# tle984x register map
Vendor: Infineon; File version: 1.9.5
CPU: CM0 r2p1, little endian, no MPU, no FPU, 2 interrupt priority bits
Registers are 32-bit, read-write, reset 0x0 unless marked. A register's access mark holds for its fields unless they carry their own. Offsets are from the block's base; [hi:lo] are bit positions; {n}, {i} and the like mark numbered series; 'fields as' and 'values as' point back to an identical list.

## SCU — System Control Unit - Digital Modules (SCU-DM) registers
Base 0x50005000
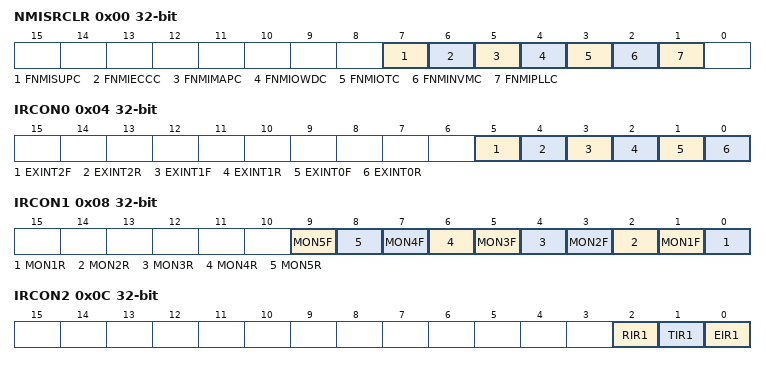
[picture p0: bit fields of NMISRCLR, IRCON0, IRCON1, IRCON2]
0x00 NMISRCLR — NMI status clear register
  [all] fields
    0=NOT_CLEARED (Interrupt event is not cleared); 1=CLEARED (Interrupt event is cleared)
  [7] FNMISUPC wo — Supply prewarning NMI flag
  [6] FNMIECCC wo — ECC error NMI flag
  [5] FNMIMAPC wo — NVM map error NMI flag
  [4] FNMIOWDC wo — Oscillator watchdog NMI flag
  [3] FNMIOTC wo — Overtemperature NMI flag
  [2] FNMINVMC wo — NVM operation complete NMI flag
  [1] FNMIPLLC wo — PLL NMI flag
0x04 IRCON0 ro — Interrupt request 0 register
  [5] EXINT2F — Interrupt flag for external interrupt 2x on falling edge
    0=NOT_OCCURED (Interrupt on falling edge event has not occurred); 1=OCCURED (Interrupt on falling edge event has occurred)
  [4] EXINT2R — Interrupt flag for external interrupt 2x on rising edge
    0=NOT_OCCURED (Interrupt on rising edge event has not occurred); 1=OCCURED (Interrupt on rising edge event has occurred)
  [3] EXINT1F — Interrupt flag for external interrupt 1x on falling edge
    values as EXINT2F
  [2] EXINT1R — Interrupt flag for external interrupt 1x on rising edge
    values as EXINT2R
  [1] EXINT0F — Interrupt flag for external interrupt 0x on falling edge
    values as EXINT2F
  [0] EXINT0R — Interrupt flag for external interrupt 0x on rising edge
    values as EXINT2R
0x08 IRCON1 ro — Interrupt request 1 register
  [2n-1] MON{n}F (n=1..5) — Interrupt flag for MON{n}x on falling edge
    values as IRCON0.EXINT2F
  [2n-2] MON{n}R (n=1..5) — Interrupt flag for MON{n}x on rising edge
    values as IRCON0.EXINT2R
0x0C IRCON2 ro — Interrupt request 2 register
  [all] fields
    0=NOT_OCCURED (Interrupt event has not occurred); 1=OCCURED (Interrupt event has occurred)
  [2] RIR1 — Receive interrupt flag for SSC1
  [1] TIR1 — Transmit interrupt flag for SSC1
  [0] EIR1 — Error interrupt flag for SSC1
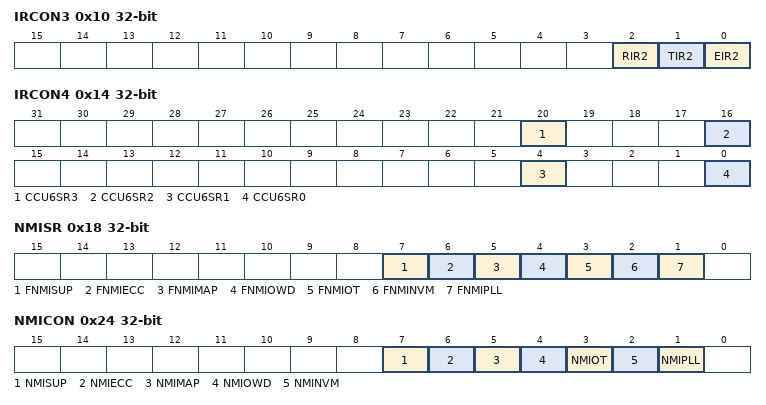
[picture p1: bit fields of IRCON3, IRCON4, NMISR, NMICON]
0x10 IRCON3 ro — Interrupt request 3 register
  [all] fields
    values as the fields of IRCON2
  [2] RIR2 — Receive interrupt flag for SSC2
  [1] TIR2 — Transmit interrupt flag for SSC2
  [0] EIR2 — Error interrupt flag for SSC2
0x14 IRCON4 ro — Interrupt request 4 register
  [all] fields
    values as the fields of IRCON2
  [20] CCU6SR3 — Interrupt flag 3 for CCU6
  [16] CCU6SR2 — Interrupt flag 2 for CCU6
  [4] CCU6SR1 — Interrupt flag 1 for CCU6
  [0] CCU6SR0 — Interrupt flag 0 for CCU6
0x18 NMISR ro — NMI status register
  [7] FNMISUP — Supply prewarning NMI flag
    0=NO_PREWARN (No supply prewarning NMI has occurred); 1=PREWARN (Supply prewarning has occurred)
  [6] FNMIECC — ECC error NMI flag
    0=NO_ECC (No uncorrectable ECC error has occurred on NVM, XRAM); 1=ECC (Uncorrectable ECC error has occurred on NVM, RAM)
  [5] FNMIMAP — NVM map error NMI flag
    0=NO_NVM (No NVM map error NMI has occurred); 1=NVM (NVM map error has occurred)
  [4] FNMIOWD — Oscillator watchdog NMI flag
    0=NO_OSCILLATOR (No oscillator watchdog NMI has occurred); 1=OSCILLATOR (Oscillator watchdog event has occurred)
  [3] FNMIOT — Overtemperature NMI flag
    0=NO_OT (No OT NMI has occurred); 1=OT (OT NMI event has occurred)
  [2] FNMINVM — NVM operation complete NMI flag
    0=NO_NVM (No NVM NMI has occurred); 1=NVM (NVM operation complete event has occurred)
  [1] FNMIPLL — PLL NMI flag
    0=NO_PLL (No PLL NMI has occurred); 1=PLL (PLL loss-of-lock to the external crystal has occurred)
0x1C IEN0 — Interrupt enable 0 register
  [31] EA — Global interrupt mask
    0=BLOCKED (All pending interrupt requests (except NMI) are blocked from the core); 1=NOT_BLOCKED (Pending interrupt requests are not blocked from the core)
0x20 VTOR — Vector table reallocation register
  [1:0] VTOR_BYP — Vector table bypass mode
    0=NOT_REMAPPED (VTOR is not remapped (ROM) (start address: 0x0000000000)); 1=RAM (VTOR is remapped to RAM (start address: 0x1800000000)); 2=BSL (VTOR is remapped to NVM (start address: 0x1100000000, begin of customer BSL region)); 3=NVM (VTOR is remapped to NVM (start address: begin of NVM linear region after customer BSL region))
0x24 NMICON — NMI control register
  [7] NMISUP — Supply prewarning NMI enable
    0=DISABLED (Supply NMI is disabled); 1=ENABLED (Supply NMI is enabled)
  [6] NMIECC — ECC error NMI enable
    0=DISABLED (ECC Error NMI is disabled); 1=ENABLED (ECC Error NMI is enabled)
  [5] NMIMAP — NVM map error NMI enable
    0=DISABLED (NVM map error NMI is disabled); 1=ENABLED (NVM map error NMI is enabled)
  [4] NMIOWD — Oscillator watchdog NMI enable
    0=DISABLED (Oscillator watchdog NMI is disabled); 1=ENABLED (Oscillator watchdog NMI is enabled)
  [3] NMIOT — NMI OT enable
    0=DISABLED (NMI OT is disabled); 1=ENABLED (NMI OT is enabled)
  [2] NMINVM — NVM operation complete NMI enable
    0=DISABLED (NVM operation complete NMI is disabled); 1=ENABLED (NVM operation complete NMI is enabled)
  [1] NMIPLL — PLL loss of lock NMI enable
    0=DISABLED (PLL loss of lock NMI is disabled); 1=ENABLED (PLL loss of lock NMI is enabled)
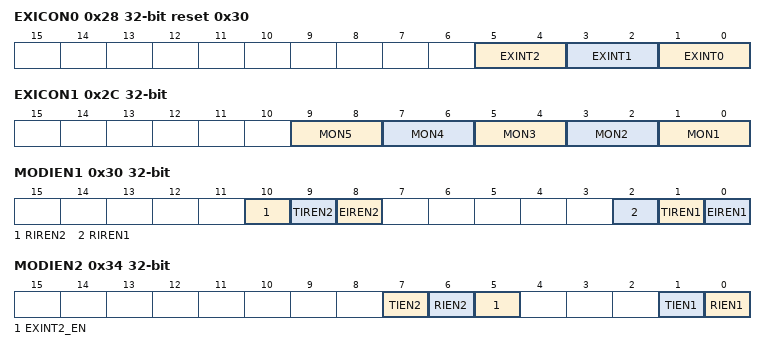
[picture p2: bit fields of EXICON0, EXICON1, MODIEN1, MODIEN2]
0x28 EXICON0 reset 0x30 — External interrupt control 0 register
  [all] fields
    0=DISABLED (Interrupt disabled); 1=RISING (Interrupt on rising edge); 2=FALLING (Interrupt on falling edge); 3=BOTH (Interrupt on both rising and falling edge)
  [5:4] EXINT2 — External interrupt 2 trigger select
  [3:2] EXINT1 — External interrupt 1 trigger select
  [1:0] EXINT0 — External interrupt 0 trigger select
0x2C EXICON1 — External interrupt control 1 register
  [all] fields
    0=DISABLED (External interrupt MON is disabled); 1=RISING (Interrupt on rising edge); 2=FALLING (Interrupt on falling edge); 3=BOTH (Interrupt on both rising and falling edge)
  [2n-1:2n-2] MON{n} (n=1..5) — MON{n} input trigger select
0x30 MODIEN1 — Peripheral interrupt enable 1 register
  [10] RIREN2 — SSC 2 receive interrupt enable
    0=DISABLED (Receive interrupt is disabled); 1=ENABLED (Receive interrupt is enabled)
  [9] TIREN2 — SSC 2 transmit interrupt enable
    0=DISABLED (Transmit interrupt is disabled); 1=ENABLED (Transmit interrupt is enabled)
  [8] EIREN2 — SSC 2 error interrupt enable
    0=DISABLED (Error interrupt is disabled); 1=ENABLED (Error interrupt is enabled)
  [2] RIREN1 — SSC 1 receive interrupt enable
    values as RIREN2
  [1] TIREN1 — SSC 1 transmit interrupt enable
    values as TIREN2
  [0] EIREN1 — SSC 1 error interrupt enable
    values as EIREN2
0x34 MODIEN2 — Peripheral interrupt enable 2 register
  [7] TIEN2 — UART 2 transmit interrupt enable
    values as MODIEN1.TIREN2
  [6] RIEN2 — UART 2 receive interrupt enable
    values as MODIEN1.RIREN2
  [5] EXINT2_EN — External interrupt 2 enable
    0=DISABLED (External interrupt is disabled); 1=ENABLED (External interrupt is enabled)
  [1] TIEN1 — UART 1 transmit interrupt enable
    values as MODIEN1.TIREN2
  [0] RIEN1 — UART 1 receive interrupt enable
    values as MODIEN1.RIREN2
0x38 MODIEN3 — Peripheral interrupt enable 3 register
  [0] IE0 — External interrupt enable
    0=DISABLED; 1=ENABLED
0x3C MODIEN4 — Peripheral interrupt enable 4 register
  [0] IE1 — External interrupt enable
    0=DISABLED; 1=ENABLED
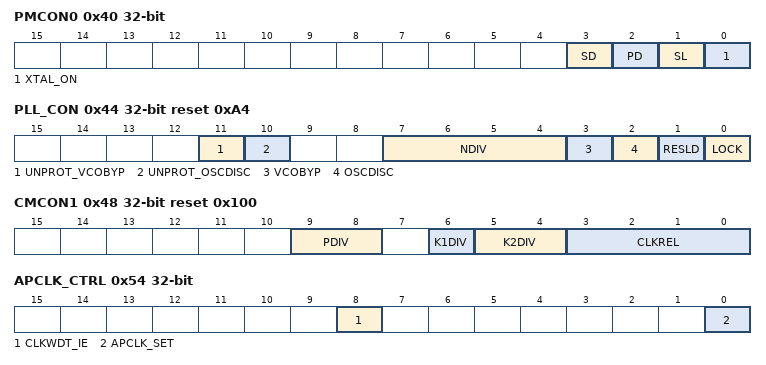
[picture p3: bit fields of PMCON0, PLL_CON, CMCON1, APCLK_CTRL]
0x40 PMCON0 — Power mode control 0 register
  [3] SD — Slow-down mode
    0=INACTIVE (No change); 1=ACTIVE (Device goes into Slow-down mode)
  [2] PD — Power-down mode
    0=INACTIVE (No change); 1=ACTIVE (Device goes into Power-down mode)
  [1] SL — Sleep mode
    0=INACTIVE (No change); 1=ACTIVE (Device goes into Sleep mode)
  [0] XTAL_ON — OSC_HP operation in STOP mode
    0=XTAL_OFF (OSC_HP (XTAL) will be suspended by hardware in STOP mode); 1=XTAL_ON (OSC_HP (XTAL) continues to operate in STOP mode, if enabled by SCU_OSC_CON.XPD)
0x44 PLL_CON reset 0xA4 — PLL control register
  [11] UNPROT_VCOBYP wo — Unprotect write access of VCO_BYP
  [10] UNPROT_OSCDISC wo — Unprotect write access of OSC_DISC
  [7:4] NDIV — PLL N-divider
    0=N = 48; 1=N = 50; 2=N = 51; 3=N = 52; 4=N = 54; 5=N = 60; 6=N = 67; 7=N = 72; 8=N = 75; 9=N = 78; 10=N = 80; 11=N = 88; 12=N = 90; 13=N =94; 14=N = 100; 15=N = 160
  [3] VCOBYP — PLL VCO bypass mode select
    0=NORMAL (Normal (or free running) operation (default)); 1=PRESCALER (Prescaler mode; VCO is bypassed (PLL output clock is derived from input clock divided by K1-divider))
  [2] OSCDISC — Oscillator disconnect
    0=CONNECTED (Oscillator is connected to the PLL); 1=DISCONNECTED (Oscillator is disconnected to the PLL)
  [1] RESLD — Restart lock detection
    0=NO (No effect); 1=RESET (Reset lock flag and restart lock detection)
  [0] LOCK ro — PLL lock status flag
    0=UNLOCKED (The frequency difference of fREF and fDIV is greater than allowed. The VCO part of the PLL can not lock on a target frequency); 1=LOCKED (The frequency difference of fREF and fDIV is small enough to enable a stable VCO operation)
0x48 CMCON1 reset 0x100 — Clock control 1 register
  [9:8] PDIV — PLL PDIV-divider
    0=4; 1=5 (default); 2=6_1; 3=6_2
  [6] K1DIV — PLL K1-divider
    0=K1 = 2; 1=K1 = 1
  [5:4] K2DIV — PLL K2-divider
    {v}=K2 = {v+2} (v=0..3)
  [3:0] CLKREL — Slow down clock divider for fCCLK generation
    0=fSYS; 1=fSYS/2; 2=fSYS/3; 3=fSYS/4; 4=fSYS/8; 5=fSYS/16; 6=fSYS/24; 7=fSYS/32; 8=fSYS/48; 9=fSYS/64; 10=fSYS/96; 11=fSYS/128; 12=fSYS/192; 13=fSYS/256; 14=fSYS/384; 15=fSYS/512
0x4C CMCON2 — Clock control 2 register
  [0] PBA0CLKREL — PBA0 clock divider
    0=Divide by 1; 1=Divide by 2
0x54 APCLK_CTRL — Analog peripheral clock control register
  [8] CLKWDT_IE — Clock watchdog interrupt enable
    0=DISABLED (Interrupt disabled); 1=ENABLED (Interrupt enabled)
  [0] APCLK_SET — Set and overtake flag for clock settings
    0=IGNORED (Clock settings are ignored (previous values are held)); 1=OVERTAKEN (Clock settings are overtaken)
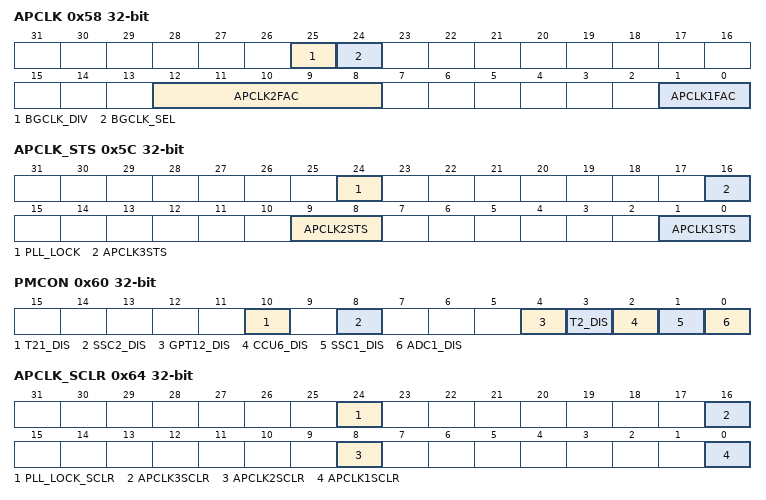
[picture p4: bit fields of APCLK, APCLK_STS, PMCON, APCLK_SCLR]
0x58 APCLK — Analog peripheral clock register
  [25] BGCLK_DIV — Bandgap clock divider
    0=Divide by 2; 1=Divide by 1
  [24] BGCLK_SEL — Bandgap clock selection
    0=LP_CLK (LP_CLK is selected); 1=fSYS is selected
  [12:8] APCLK2FAC — Slow down clock divider for TFILT_CLK generation
    0=fSYS; {v}=fSYS/{v+1} (v=1..11); 30=fSYS/24; 31=fSYS/32
  [1:0] APCLK1FAC — Analog module clock factor
    {v}=Divide by {v+1} (v=0..3)
0x5C APCLK_STS ro — Analog peripheral clock status register
  [24] PLL_LOCK — PLL LOCK status
    0=NOT_LOCKED (PLL has not locked); 1=LOCKED (PLL has locked)
  [16] APCLK3STS — Loss of clock status
    0=NO_LOSS (No loss of clock); 1=LOSS (Loss of lock occurred)
  [9:8] APCLK2STS — Analog peripherals clock status
    0=RANGE (The TFILT_CLK clock is in the required range); 1=HIGHER (The TFILT_CLK clock exceeds the higher limit); 2=LOWER (The TFILT_CLK clock exceeds the lower limit); 3=OUTSIDE (The TFILT_CLK clock is not inside the specified limit)
  [1:0] APCLK1STS — Analog peripherals clock status
    0=RANGE (The MI_CLK clock is in the required range); 1=HIGHER (The MI_CLK clock exceeds the higher limit); 2=LOWER (The MI_CLK clock exceeds the lower limit); 3=OUTSIDE (The MI_CLK clock is not inside the specified limit)
0x60 PMCON — Peripheral management control register
  [10] T21_DIS — T21 disable request, active high
    0=NORMAL (T21 is in normal operation (default)); 1=DISABLE (Request to disable the T21)
  [8] SSC2_DIS — SSC2 disable request, active high
    0=NORMAL (SSC is in normal operation (default)); 1=DISABLE (Request to disable the SSC)
  [4] GPT12_DIS — General purpose timer 12 disable request, active high
    0=NORMAL (GPT12 is in normal operation (default)); 1=DISABLE (Request to disable the GPT12)
  [3] T2_DIS — T2 disable request, active high
    0=NORMAL (T2 is in normal operation (default)); 1=DISABLE (Request to disable the T2)
  [2] CCU6_DIS — CCU6 disable request, active high
    0=NORMAL (CCU6 is in normal operation (default)); 1=DISABLE (Request to disable the CCU6)
  [1] SSC1_DIS — SSC1 disable request, active high
    values as SSC2_DIS
  [0] ADC1_DIS — ADC1 disable request, active high
    0=NORMAL (ADC1 is in normal operation (default)); 1=DISABLE (Request to disable the ADC)
0x64 APCLK_SCLR — Analog peripheral clock status clear register
  [24] PLL_LOCK_SCLR wo — PLL lock status clear
  [16] APCLK3SCLR wo — Analog peripherals clock 3 status clear
  [8] APCLK2SCLR wo — Analog peripherals clock status clear
  [0] APCLK1SCLR wo — Analog peripherals clock status clear
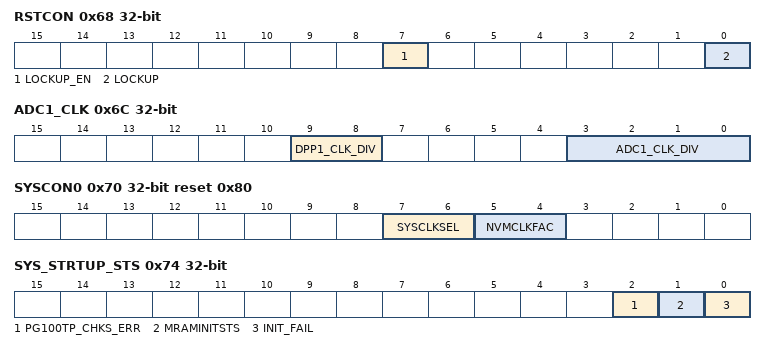
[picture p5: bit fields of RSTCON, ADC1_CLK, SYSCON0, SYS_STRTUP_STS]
0x68 RSTCON — Reset control register
  [7] LOCKUP_EN — Lockup reset enable flag
    0=DISABLED (Lockup is disabled); 1=ENABLED (Lockup is enabled)
  [0] LOCKUP — Lockup flag
    0=NOT_ACTIVE (Lockup status not active); 1=ACTIVE (Lockup status active)
0x6C ADC1_CLK — ADC1 peripheral clock register
  [9:8] DPP1_CLK_DIV — ADC1 post processing clock divider
    {v}=Divide by {v+1} (v=0..3)
  [3:0] ADC1_CLK_DIV — ADC1 clock divider
    0=Divide by {$n+1}; 1=Divide by {$n+1}; 2=Divide by {$n+1}; 3=Divide by {$n+1}; 4=Divide by {$n+1}; 6=Divide by 16
0x70 SYSCON0 reset 0x80 — System control 0 register
  [7:6] SYSCLKSEL — System clock select
    0=PLL (The PLL clock output signal fPLL is used); 1=OSC (The direct clock input from fOSC is used); 2=LP_CLK (The direct low-precision clock input from fLP_CLK is used); 3=INTOSC (The direct input from internal oscillator fINTOSC is used)
  [5:4] NVMCLKFAC — NVM access clock factor
    {v}=Divide by {v+1} (v=0..3)
0x74 SYS_STRTUP_STS — System startup status register
  [2] PG100TP_CHKS_ERR — 100 TP Page checksum error
    0=OK (Initialization of trimming parameters from NMV was successful (checksum was correct)); 1=NOK (Initialization of trimming parameter from NMV was not successful (checksum was notcorrect). As a backup default values form Boot-ROM are used)
  [1] MRAMINITSTS — Map RAM initialization status
    0=NO_FAIL (Map RAM initialization was successful); 1=FAIL (Map RAM initialization was not successful)
  [0] INIT_FAIL — Initialization at startup failed
    0=NO_ERROR (No initialization error at startup); 1=ERROR (Initialization error at startup)
0x78 WAKECON — Wake-up interrupt control register
  [0] WAKEUPEN — Wake-up interrupt enable
    0=DISABLED (Wake-up interrupt is disabled); 1=ENABLED (Wake-up interrupt is enabled)
0x7C IRCON5 ro — Interrupt request 5 register
  [0] WAKEUP — Interrupt flag for wake-up
    values as the fields of IRCON2
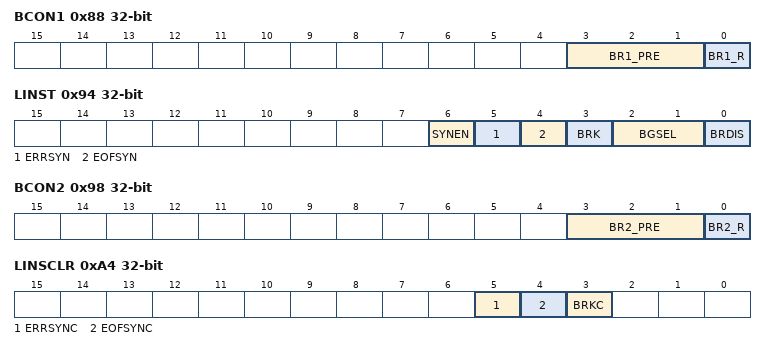
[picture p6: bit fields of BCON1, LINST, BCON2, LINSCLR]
0x88 BCON1 — Baud-rate control 1 register
  [3:1] BR1_PRE — Prescaler bit
    0=fDIV = fPCLK; 1=fDIV = fPCLK/2; 2=fDIV = fPCLK/4; 3=fDIV = fPCLK/8; 4=fDIV = fPCLK/16; 5=fDIV = fPCLK/32
  [0] BR1_R — Baud-rate generator run control bit
    0=DISABLED (Baud-rate generator disabled); 1=ENABLED (Baud-rate generator enabled)
0x8C BGL1 — Baud-rate timer/reload, low byte 1 register
  [4:0] BG1_FD_SEL — Fractional divider selection
0x90 BG1 — Baud-rate timer/reload 1 register
  [10:0] BG1_BR_VALUE — Baud-rate timer/reload value UART1
    0=BYPASSED (Baud-rate timer is bypassed); 1=1; 2=2; 0x7FE=2046; 0x7FF=2047
0x94 LINST — LIN status register
  [6] SYNEN — End of SYN byte and SYN byte error interrupts enable
    0=DISABLED (End of SYN byte and SYN byte error interrupts are not enabled); 1=ENABLED (End of SYN byte and SYN byte error interrupts are enabled)
  [5] ERRSYN ro — SYN byte error interrupt flag
    0=NOT_DETECTED (Error is not detected in SYN byte); 1=DETECTED (Error is detected in SYN byte)
  [4] EOFSYN ro — End of SYN byte interrupt flag
    0=NOT_DETECTED (End of SYN byte is not detected); 1=DETECTED (End of SYN byte is detected)
  [3] BRK ro — Break field flag
    0=NOT_DETECTED (Break field is not detected); 1=DETECTED (Break field is detected)
  [2:1] BGSEL — Baud-rate select for detection
  [0] BRDIS — Baud-rate detection disable
    0=ENABLED (Break/sync detection is enabled); 1=DISABLED (Break/sync detection is disabled)
0x98 BCON2 — Baud-rate control 2 register
  [3:1] BR2_PRE — Prescaler bit
    values as BCON1.BR1_PRE
  [0] BR2_R — Baud-rate generator run control bit
    values as BCON1.BR1_R
0x9C BGL2 — Baud-rate timer/reload, low byte 2 register
  [4:0] BG2_FD_SEL — Fractional divider selection
0xA0 BG2 — Baud-rate timer/reload 2 register
  [10:0] BG2_BR_VALUE — Baud-rate timer/reload value UART2
    values as BG1.BG1_BR_VALUE
0xA4 LINSCLR — LIN status clear register
  [5] ERRSYNC wo — SYN byte error interrupt flag
    0=NOT_CLEARED (Error in SYN byte not cleared); 1=CLEARED (Error in SYN byte cleared)
  [4] EOFSYNC wo — End of SYN byte interrupt flag clear
    0=NOT_CLEARED (End of SYN byte is not cleared); 1=CLEARED (End of SYN byte is cleared)
  [3] BRKC wo — Break field flag clear
    0=NOT_CLEARED (Break field is not cleared); 1=CLEARED (Break field is cleared)
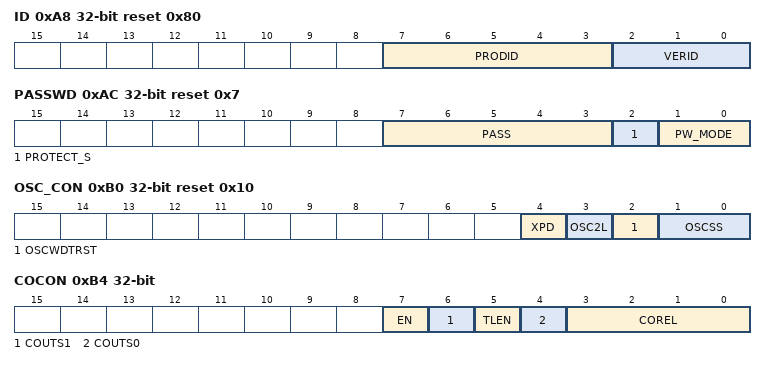
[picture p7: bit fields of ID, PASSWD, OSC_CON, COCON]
0xA8 ID reset 0x80 — Identity register
  [7:3] PRODID ro — Product ID
  [2:0] VERID — Version ID
0xAC PASSWD reset 0x7 — Password register
  [7:3] PASS — Password bits
    19=OPENED (Opens access to writing of all protected bits); 21=CLOSED (Closes access to writing of all protected bits); 24=ENABLED (Enables writing of the bit field MODE)
  [2] PROTECT_S ro — Bit protection signal status bit
    0=NOT_PROTECTED (Software is able to write to all protected bits); 1=PROTECTED (Software is unable to write to any protected bits)
  [1:0] PW_MODE — Bit protection scheme control bit
    0=DISABLED (Scheme disabled); 3=ENABLED (Scheme enabled (default))
0xB0 OSC_CON reset 0x10 — OSC control register
  [4] XPD — XTAL (OSC_HP) power down control
    0=NOT_POWERED (XTAL (OSC_HP) is not powered down); 1=POWERED (XTAL (OSC_HP) is powered down)
  [3] OSC2L ro — OSC-too-low condition flag
    0=ABOVE (fOSC is above threshold); 1=BELOW (fOSC is below threshold)
  [2] OSCWDTRST — Oscillator watchdog reset
    0=NO_EFFECT; 1=RESET (Reset OSC2L flag and restart the oscillator watchdog of the PLL)
  [1:0] OSCSS — Oscillator source select
    0=PLL_SYNC (PLL internal oscillator OSC_PLL (fINT) is selected synchronously as fR); 1=XTAL (XTAL (fOSC from OSC_HP) is selected synchronously as fR); 2=PLL_ASYNC (PLL internal oscillator OSC_PLL (fINT) is selected asynchronously as fR); 3=PLL_ASYNC (PLL internal oscillator OSC_PLL (fINT) is selected asynchronously as fR)
0xB4 COCON — Clock output control register
  [7] EN — CLKOUT enable
    0=NO_EXTERNAL (No external clock signal is provided); 1=EXTERNAL (The configured external clock signal is provided)
  [6] COUTS1 — Clock out source select bit 1
    0=fCCLK is selected; 1=COUTS0 (Based on setting of COUTS0)
  [5] TLEN — Toggle latch enable
    0=DISABLED (Toggle latch is disabled. Clock output frequency is chosen by the bit field COREL); 1=ENABLED (Toggle latch is enabled. Clock output frequency is half of the frequency that is chosen by the bit field COREL. The resulting output frequency has 50% duty cycle)
  [4] COUTS0 — Clock out source select bit 0
    0=OSCILLATOR (Oscillator output frequency is selected); 1=COREL (Clock output frequency is chosen by the bit field COREL)
  [3:0] COREL — Clock output divider
    0=fSYS; 1=fSYS/2; 2=fSYS/3; 3=fSYS/4; 4=fSYS/6; 5=fSYS/8; 6=fSYS/10; 7=fSYS/12; 8=fSYS/14; 9=fSYS/16; 10=fSYS/18; 11=fSYS/20; 12=fSYS/24; 13=fSYS/32; 14=fSYS/36; 15=fSYS/40
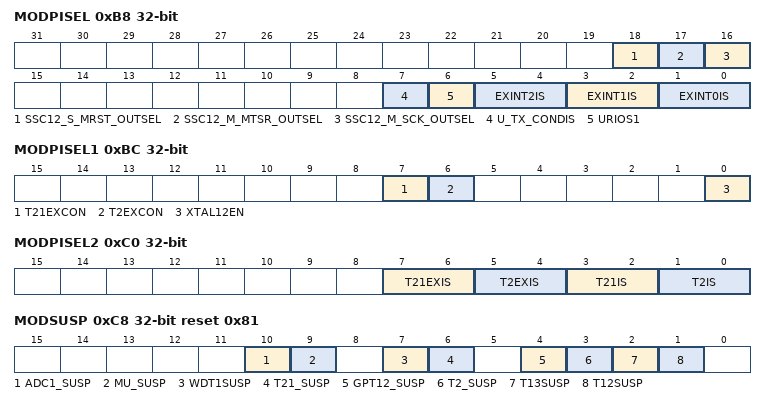
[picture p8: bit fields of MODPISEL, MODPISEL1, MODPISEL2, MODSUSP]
0xB8 MODPISEL — Peripheral input select register
  [18] SSC12_S_MRST_OUTSEL — Output selection for SSC12_S_MRST
    0=SSC1 (SSC1_S_MRST); 1=SSC2 (SSC2_S_MRST)
  [17] SSC12_M_MTSR_OUTSEL — Output selection for SSC12_M_MTSR
    0=SSC1 (SSC1_M_MTSR); 1=SSC2 (SSC2_M_MTSR)
  [16] SSC12_M_SCK_OUTSEL — Output selection for SSC12_M_SCK
    0=SSC1 (SSC1_M_SCK); 1=SSC2 (SSC2_M_SCK)
  [7] U_TX_CONDIS — TRX input select
    0=UART (Transceiver TXD input connected to UART1_TXD output); 1=GPIO (Transceiver TXD input connected to GPIO)
  [6] URIOS1 — UART1 input select
    0=TRX (UART1 receiver input UART1_RXD (connected to transceiver)); 1=GPIO (UART1 receiver input UART1_RXD (connected to GPIO))
  [5:4] EXINT2IS — External interrupt 2 input select
    {v}=EXINT2_{v} (External interrupt input EXINT2_{v} is selected) (v=0..3)
  [3:2] EXINT1IS — External interrupt 1 input select
    {v}=EXINT1_{v} (External interrupt input EXINT1_{v} is selected) (v=0..3)
  [1:0] EXINT0IS — External interrupt 0 input select
    {v}=EXINT0_{v} (External interrupt input EXINT0_{v} is selected) (v=0..3)
0xBC MODPISEL1 — Peripheral input select 1 register
  [7] T21EXCON — Timer 21 external input control
    0=SELECT (Timer21 input T21EX is selected by bit field SCU_MODPISEL2.T21EXIS); 1=CONNECT (Timer21 input T21EX is connected to signal from CCU6 (Output >cc6_ch0))
  [6] T2EXCON — Timer 2 external input control
    0=SELECT (Timer2 input T2EX is selected by bit field SCU_MODPISEL2.T2EXIS); 1=CONNECT (Timer2 input T2EX is connected to signal from CCU6 (Output>cc6_cout60))
  [0] XTAL12EN — Pins XTAL1/2 enable bit
    0=NOT_AVAILABLE (Pins XTAL1/2 is not available. This setting overrides the OSC_CON.XPD setting); 1=AVAILABLE (Pins XTAL1/2 is available)
0xC0 MODPISEL2 — Peripheral input select 2 register
  [7:6] T21EXIS — Timer 21 external input select
    {v}=T21EX_{v} (Timer21 input T21EX_{v} is selected) (v=0..3)
  [5:4] T2EXIS — Timer 2 external input select
    0=T2EX_0 (Timer2 input T2EX_0 is selected); 1=T2EX_1 (Timer2 input T2EX_1 is selected); 2=T2EX_2 (Timer2 input T2EX_2 i selected); 3=T2EX_3 (Timer2 input T2EX_3 is selected)
  [3:2] T21IS — Timer 21 input select
    0=T21_0 (Timer21 input T21_0 is selected); 1=T21_1 (Timer21 input T21_1 is selected); 2=T21_2 (Timer21 input T21_2 is selected)
  [1:0] T2IS — Timer 2 input select
    0=T2_0 (Timer2 input T2_0 is selected); 1=T2_1 (Timer2 input T2_1 is selected); 2=T2_2 (Timer2 input T2_2 is selected)
0xC4 MODPISEL3 — Peripheral input select 3 register
  [6] URIOS2 — UART2 input select
    0=GPIO (UART2 receiver input UART2_RXD (connected to GPIO)); 1=GPIO (UART2 receiver input UART2_RXD (connected to GPIO))
0xC8 MODSUSP reset 0x81 — Module suspend control register
  [10] ADC1_SUSP — ADC1 unit debug suspend bit
    0=NOT_SUSPENDED (ADC1 will not be suspended); 1=SUSPENDED (ADC1 will be suspended)
  [9] MU_SUSP — Measurement unit debug suspend bit
    0=NOT_SUSPENDED (MU will not be suspended); 1=SUSPENDED (MU will be suspended)
  [7] WDT1SUSP — Watchdog timer 1 debug suspend bit
    0=NOT_SUSPENDED (WDT1 will not be suspended); 1=SUSPENDED (WDT1 will be suspended)
  [6] T21_SUSP — Timer 21 debug suspend bit
    0=NOT_SUSPENDED (Timer21 will not be suspended); 1=SUSPENDED (Timer21 will be suspended)
  [4] GPT12_SUSP — GPT12 debug suspend bit
    0=NOT_SUSPENDED (GPT12 will not be suspended); 1=SUSPENDED (GPT12 will be suspended)
  [3] T2_SUSP — Timer 2 debug suspend bit
    0=NOT_SUSPENDED (Timer2 will not be suspended); 1=SUSPENDED (Timer2 will be suspended)
  [2] T13SUSP — Timer 13 debug suspend bit
    0=NOT_SUSPENDED (Timer13 in capture/compare unit will not be suspended); 1=SUSPENDED (Timer13 in capture/compare unit will be suspended)
  [1] T12SUSP — Timer 12 debug suspend bit
    0=NOT_SUSPENDED (Timer12 in capture/compare unit will not be suspended); 1=SUSPENDED (Timer12 in capture/compare unit will be suspended)
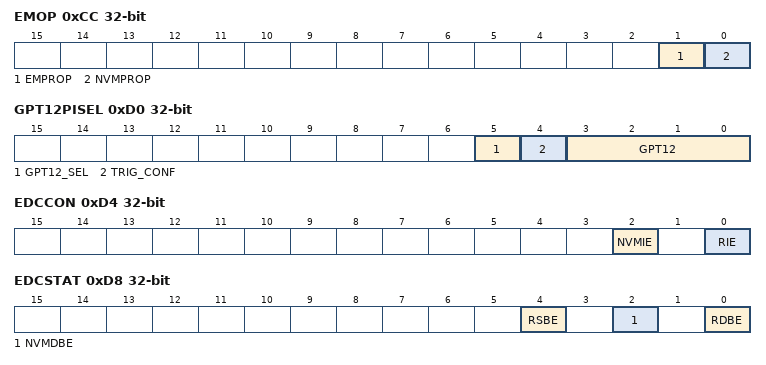
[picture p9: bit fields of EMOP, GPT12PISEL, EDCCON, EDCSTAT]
0xCC EMOP — Emergency and program operation status register
  [1] EMPROP — Emergency program operation status bit
    0=NOT_STARTED (No emergency program operation is started); 1=STARTED (Emergency program operation is started)
  [0] NVMPROP — NVM program operation status bit
    0=NOT_STARTED (No NVM program operation is started); 1=STARTED (NVM program operation is started)
0xD0 GPT12PISEL — GPT12 peripheral input select register
  [5] GPT12_SEL — CCU6 trigger configuration
    0=T21 (CCU6_INT is triggered by Timer21); 1=GPT12 (CCU6_INT is triggered by GPT12PISEL.GPT12)
  [4] TRIG_CONF — CCU6 trigger Configuration
    0=ONE (Trigger is just for one measurement (default)); 1=NEXT (Trigger is present until next input edge (selected by GPT12) \u2013 continuous measurement)
  [3:0] GPT12 — GPT12 T3INB/T4IND input select
    0=CC60; 1=CC61; 2=CC62; 3=T12_ZM; 4=T12_PM; 5=T12_CM0; 6=T12_CM1; 7=T12_CM2; 8=T13_PM; 9=T13_ZM; 10=T13_CM; 11=ANY (Any pos or neg edge on CC60/61/62)
0xD4 EDCCON — Error detection and correction control register
  [2] NVMIE — NVM double bit ECC error interrupt enable
    0=false (No NMI is generated when a double bit ECC error occurs reading NVM); 1=true (An NMI is generated when a double bit ECC error occurs reading NVM)
  [0] RIE — RAM double bit ECC error interrupt enable
    0=false (No NMI is generated when a double bit ECC error occurs reading RAM); 1=true (An NMI is generated when a double bit ECC error occurs reading RAM)
0xD8 EDCSTAT ro — Error detection and correction status register
  [4] RSBE — RAM single bit error
    0=false (No single bit error on RAM has occurred); 1=true (A single bit error on RAM has occurred)
  [2] NVMDBE — NVM double bit error
    0=false (No double bit error on NVM has occurred); 1=true (A double bit error on NVM has occurred)
  [0] RDBE — RAM double bit error
    0=false (No double bit error on RAM has occurred); 1=true (A double bit error on RAM has occurred)
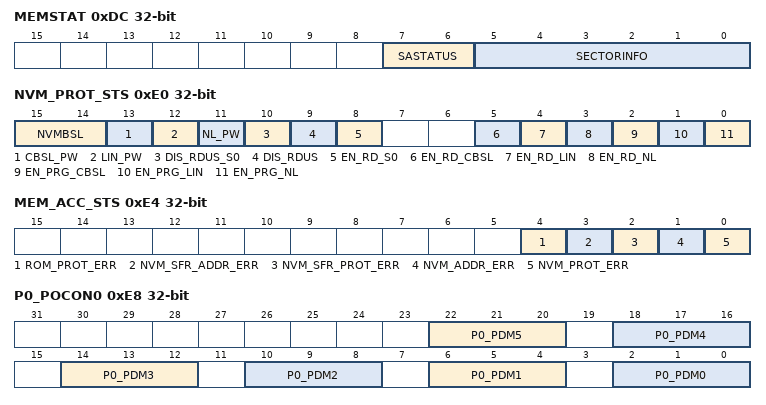
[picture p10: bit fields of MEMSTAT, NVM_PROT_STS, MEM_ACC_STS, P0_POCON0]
0xDC MEMSTAT — Memory status register
  [7:6] SASTATUS — Service algorithm status
    0=SECTORINFO (Depending on SECTORINFO); 1=SUCCESS (SA execution is successful); 2=NO_SUCCESS (SA execution is not successful. Map error exists in the mapped sector); 3=NO_SUCCESS (SA execution is not successful. Map error exists in the mapped sector)
  [5:0] SECTORINFO — Sector information
0xE0 NVM_PROT_STS — NVM protection status register
  [15:14] NVMBSL — CBSL region size definition
    0=CBSL size is 4 K; 1=CBSL size is 8 K; 2=CBSL size is 12 K; 3=CBSL size is 16 K
  [13] CBSL_PW — Status of CBSL region password/protection
    0=NOT_PROTECTED (CBSL region password is not installed; CBSL region is not protected); 1=PROTECTED (CBSL region password is installed; CBSL region is protected)
  [12] LIN_PW — Status of linear region password/protection
    0=NOT_PROTECTED (Linear region password is not installed; linear region is not protected); 1=PROTECTED (Linear region password is installed; linear region is protected)
  [11] NL_PW — Status of non-linear region password/protection
    0=NOT_PROTECTED (Non-linear region password is not installed; linear region is not protected); 1=PROTECTED (Non-linear region password is installed; linear region is protected)
  [10] DIS_RDUS_S0 — Configuration of NVM read protection for sector 0 with EN_RD_S0 = 0
    0=NVM_READ_S0_UNSAVE (Only active when nvm_read_S0_unsafe_i = 1 and not for nvm_read_S0_unsafe_i = 0); 1=INDEPENDENT (Independent from nvm_read_S0_unsafe_i; also write accesses to sector 0 are prevented)
  [9] DIS_RDUS — Configuration of NVM read protection for sector 1...n with EN_RD_* = 0
    0=NVM_READ_UNSAVE (Only active when nvm_read_unsafe_i = 1 and not for nvm_read_unsafe_i = 0); 1=INDEPENTENT (Independent from nvm_read_unsafe_i; also write accesses to sector 1...n are prevented)
  [8] EN_RD_S0 — NVM read protection for sector 0
    0=NO_READ (The data in sector 0 can not be read over AHB-Lite interface); 1=READ (The data in sector 0 can be read over AHB-Lite interface)
  [5] EN_RD_CBSL — NVM read protection of data in CBSL region
    0=NO_READ (The data in region defined by NVMBSL can not be read); 1=READ (The data in region defined by NVMBSL sectors of can be read)
  [4] EN_RD_LIN — NVM read protection of data in linear sectors
    0=NO_READ (The data in sectors of the linearly mapped area can not be read); 1=READ (The data in sectors of the linearly mapped area can be read)
  [3] EN_RD_NL — NVM read protection of data in non-linear sectors
    0=NO_READ (The data in sectors of the non-linearly mapped area can not be read); 1=READ (The data in sectors of the non-linearly mapped area can be read)
  [2] EN_PRG_CBSL — NVM protection of data in CBSL region
    0=NO_CHANGE (The data in region defined by NVMBSL can not be changed); 1=CHANGE (The data in region defined by NVMBSL can be changed (erased or written))
  [1] EN_PRG_LIN — NVM protection of data in linear sectors
    0=NO_CHANGE (The data in sectors of the linearly mapped area can not be changed); 1=CHANGE (The data in sectors of the linearly mapped area can be changed (erased or written))
  [0] EN_PRG_NL — NVM protection of data in non-linear sectors
    0=NO_CHANGE (The data in sectors of the non-linearly mapped area can not be changed); 1=CHANGE (The data in sectors of the non-linearly mapped area can be changed (erased or written))
0xE4 MEM_ACC_STS ro — Memory access status register
  [all] fields
    0=NO_ERROR (No Protection error); 1=ERROR (Protection error)
  [4] ROM_PROT_ERR — ROM access protection
  [3] NVM_SFR_ADDR_ERR — NVM SFR address protection
  [2] NVM_SFR_PROT_ERR — NVM SFR access protection
  [1] NVM_ADDR_ERR — NVM address protection
  [0] NVM_PROT_ERR — NVM access protection
0xE8 P0_POCON0 — Port output control register
  [22:20] P0_PDM5 — P0.5 port driver mode
    0=STRONG_SHARP (Strong driver and sharp edge mode); 1=STRONG_MEDIUM (Strong driver and medium edge mode); 2=STRONG_SOFT (Strong driver and soft edge mode); 3=WEAK_1 (Weak driver 1); 4=MEDIUM_1 (Medium driver 1); 5=MEDIUM_2 (Medium driver 2); 6=MEDIUM_3 (Medium driver 3); 7=WEAK_2 (Weak driver 2)
  [18:16] P0_PDM4 — P0.4 port driver mode
    values as P0_PDM5
  [14:12] P0_PDM3 — P0.3 port driver mode
    values as P0_PDM5
  [10:8] P0_PDM2 — P0.2 port driver mode
    values as P0_PDM5
  [6:4] P0_PDM1 — P0.1 port driver mode
    0=MEDIUM_1 (Medium driver 1); 3=WEAK_1 (Weak driver 1); 4=MEDIUM_2 (Medium driver 2); 5=MEDIUM_3 (Medium driver 3); 6=MEDIUM_4 (Medium driver 4); 7=WEAK_2 (Weak driver 2)
  [2:0] P0_PDM0 — P0.0 port driver mode
    values as P0_PDM1
0xF4 TCCR — Temperature compensation control register
  [1:0] TCC — Temperature compensation control
    0=_40_0 (Tj: -40deg C to 0deg C); 1=0_40 (Tj: 0deg C to 40deg C); 2=40_80 (Tj: 40deg C to 80deg C); 3=80_150 (Tj: 80deg C to 150deg C)
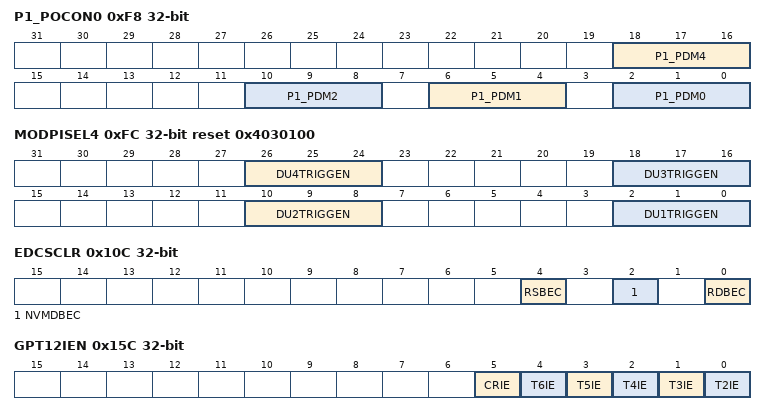
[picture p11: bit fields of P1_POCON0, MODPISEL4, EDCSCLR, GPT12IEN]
0xF8 P1_POCON0 — Port output control register
  [18:16] P1_PDM4 — P1.4 port driver mode
    values as P0_POCON0.P0_PDM5
  [10:8] P1_PDM2 — P1.2 port driver mode
    values as P0_POCON0.P0_PDM1
  [6:4] P1_PDM1 — P1.1 port driver mode
    values as P0_POCON0.P0_PDM1
  [2:0] P1_PDM0 — P1.0 port driver mode
    values as P0_POCON0.P0_PDM1
0xFC MODPISEL4 reset 0x4030100 — Peripheral input select 4 register
  [26:24] DU4TRIGGEN — Differential unit trigger enable
    0=CC60 (CC60 is selected); 1=CC61 (CC61 is selected); 2=CC62 (CC62 is selected); 3=COUT60 (COUT60 is selected); 4=COUT61 (COUT61 is selected); 5=COUT62 (COUT62 is selected); 6=T3OUT (T3OUT is selected); 7=COUT63 (COUT63 is selected)
  [18:16] DU3TRIGGEN — Differential unit trigger enable
    values as DU4TRIGGEN
  [10:8] DU2TRIGGEN — Differential unit trigger enable
    values as DU4TRIGGEN
  [2:0] DU1TRIGGEN — Differential unit trigger enable
    0=CC60 (CC60 is selected); 1=CC61 (CC61 is selected); 2=CC62 (CC62 is selected); 3=COUT60 (COUT60 is selected); 4=COUT61 (COUT61 is selected); 5=COUT62 (COUT62 is selected); 6=T3OUT (T3OUT is selected); 7=COUT6 (COUT63 is selected)
0x10C EDCSCLR — Error detection and correction status clear register
  [4] RSBEC wo — RAM single bit error clear
    0=NOT_CLEARED (A single bit error on RAM is not cleared); 1=CLEARED (A single bit error on RAM is cleared)
  [2] NVMDBEC wo — NVM double bit error clear
    0=NOT_CLEARED (A double bit error on NVM is not cleared); 1=CLEARED (A double bit error on NVM is cleared)
  [0] RDBEC wo — RAM double bit error clear
    0=NOT_CLEARED (A double bit error on RAM is not cleared); 1=CLEARED (A double bit error on RAM is cleared)
0x15C GPT12IEN — General purpose timer 12 interrupt enable register
  [all] fields
    0=DISABLED (Interrupt is disabled); 1=ENABLED (Interrupt is enabled)
  [5] CRIE — GPT12 capture and reload interrupt enable
  [n-2] T{n}IE (n=2..6) — GPT12 T{n} interrupt enable
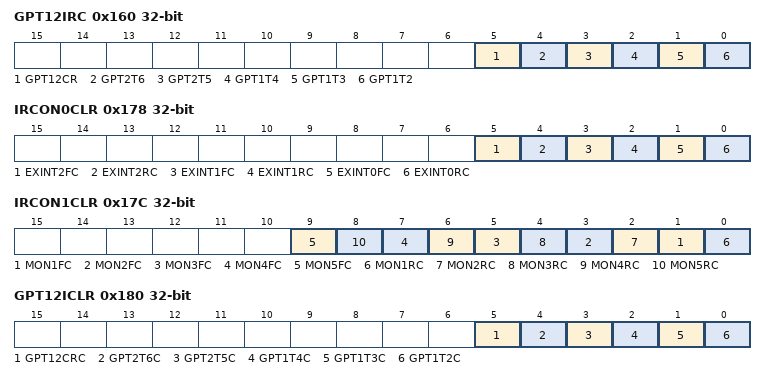
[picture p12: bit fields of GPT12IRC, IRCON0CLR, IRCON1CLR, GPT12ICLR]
0x160 GPT12IRC ro — Timer and counter control/status register
  [5] GPT12CR — GPT12 capture reload interrupt status
    0=NOT_OCCURRED (No capture reload interrupt has occurred); 1=OCCURRED (Capture reload interrupt has occurred)
  [4] GPT2T6 — GPT module 2 Timer6 interrupt status
    0=NOT_OCCURRED (No Timer6 interrupt has occurred); 1=OCCURRED (Timer6 interrupt has occurred)
  [3] GPT2T5 — GPT module 2 Timer5 interrupt status
    0=NOT_OCCURRED (No Timer5 interrupt has occurred); 1=OCCURRED (Timer5 interrupt has occurred)
  [2] GPT1T4 — GPT module 1 Timer4 interrupt status
    0=NOT_OCCURRED (No Timer4 interrupt has occurred); 1=OCCURRED (Timer4 interrupt has occurred)
  [1] GPT1T3 — GPT module 1 Timer3 interrupt status
    0=NOT_OCCURRED (No Timer3 interrupt has occurred); 1=OCCURRED (Timer3 interrupt has occurred)
  [0] GPT1T2 — GPT module 1 Timer2 interrupt status
    0=NOT_OCCURRED (No Timer2 interrupt has occurred); 1=OCCURRED (Timer2 interrupt has occurred)
0x178 IRCON0CLR — Interrupt request 0 clear register
  [all] fields
    values as the fields of NMISRCLR
  [5] EXINT2FC wo — Interrupt flag for external interrupt 2x on falling edge
  [4] EXINT2RC wo — Interrupt flag for external interrupt 2x on rising edge
  [3] EXINT1FC wo — Interrupt flag for external interrupt 1x on falling edge
  [2] EXINT1RC wo — Interrupt flag for external interrupt 1x on rising edge
  [1] EXINT0FC wo — Interrupt flag for external interrupt 0x on falling edge
  [0] EXINT0RC wo — Interrupt flag for external interrupt 0x on rising edge
0x17C IRCON1CLR — Interrupt request 1 clear register
  [all] fields
    values as the fields of NMISRCLR
  [2n-1] MON{n}FC wo (n=1..5) — Interrupt flag for MON{n}x on falling edge
  [2n-2] MON{n}RC wo (n=1..5) — Interrupt flag for MON{n}x on rising edge
0x180 GPT12ICLR — Timer and counter control/status clear register
  [all] fields
    values as the fields of NMISRCLR
  [5] GPT12CRC wo — GPT12 capture reload interrupt status
  [4] GPT2T6C wo — GPT module 2 Timer6 interrupt status
  [3] GPT2T5C wo — GPT module 2 Timer5 interrupt status
  [2] GPT1T4C wo — GPT module 1 Timer4 interrupt status
  [1] GPT1T3C wo — GPT module 1 Timer3 interrupt status
  [0] GPT1T2C wo — GPT module 1 Timer2 interrupt status
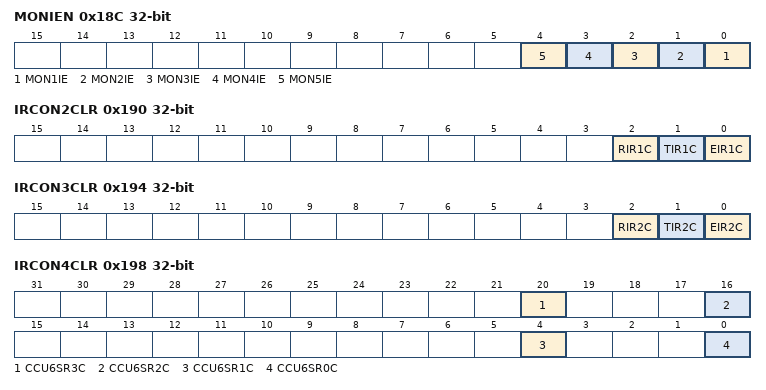
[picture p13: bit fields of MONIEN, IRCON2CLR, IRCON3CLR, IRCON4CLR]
0x18C MONIEN — Monitoring input interrupt enable register
  [all] fields
    0=DISABLED; 1=ENABLED
  [n-1] MON{n}IE (n=1..5) — MON{n} interrupt enable
0x190 IRCON2CLR — Interrupt request 2 clear register
  [all] fields
    values as the fields of NMISRCLR
  [2] RIR1C wo — Receive interrupt flag for SSC1
  [1] TIR1C wo — Transmit interrupt flag for SSC1
  [0] EIR1C wo — Error interrupt flag for SSC1
0x194 IRCON3CLR — Interrupt request 3 clear register
  [all] fields
    values as the fields of NMISRCLR
  [2] RIR2C wo — Receive interrupt flag for SSC2
  [1] TIR2C wo — Transmit interrupt flag for SSC2
  [0] EIR2C wo — Error interrupt flag for SSC2
0x198 IRCON4CLR — Interrupt request 4 clear register
  [all] fields
    values as the fields of NMISRCLR
  [20] CCU6SR3C wo — Interrupt flag 3 for CCU6
  [16] CCU6SR2C wo — Interrupt flag 2 for CCU6
  [4] CCU6SR1C wo — Interrupt flag 1 for CCU6
  [0] CCU6SR0C wo — Interrupt flag 0 for CCU6
0x19C IRCON5CLR — Interrupt request 5 clear register
  [0] WAKEUPC wo — Clear flag for wake-up interrupt
    values as the fields of NMISRCLR
